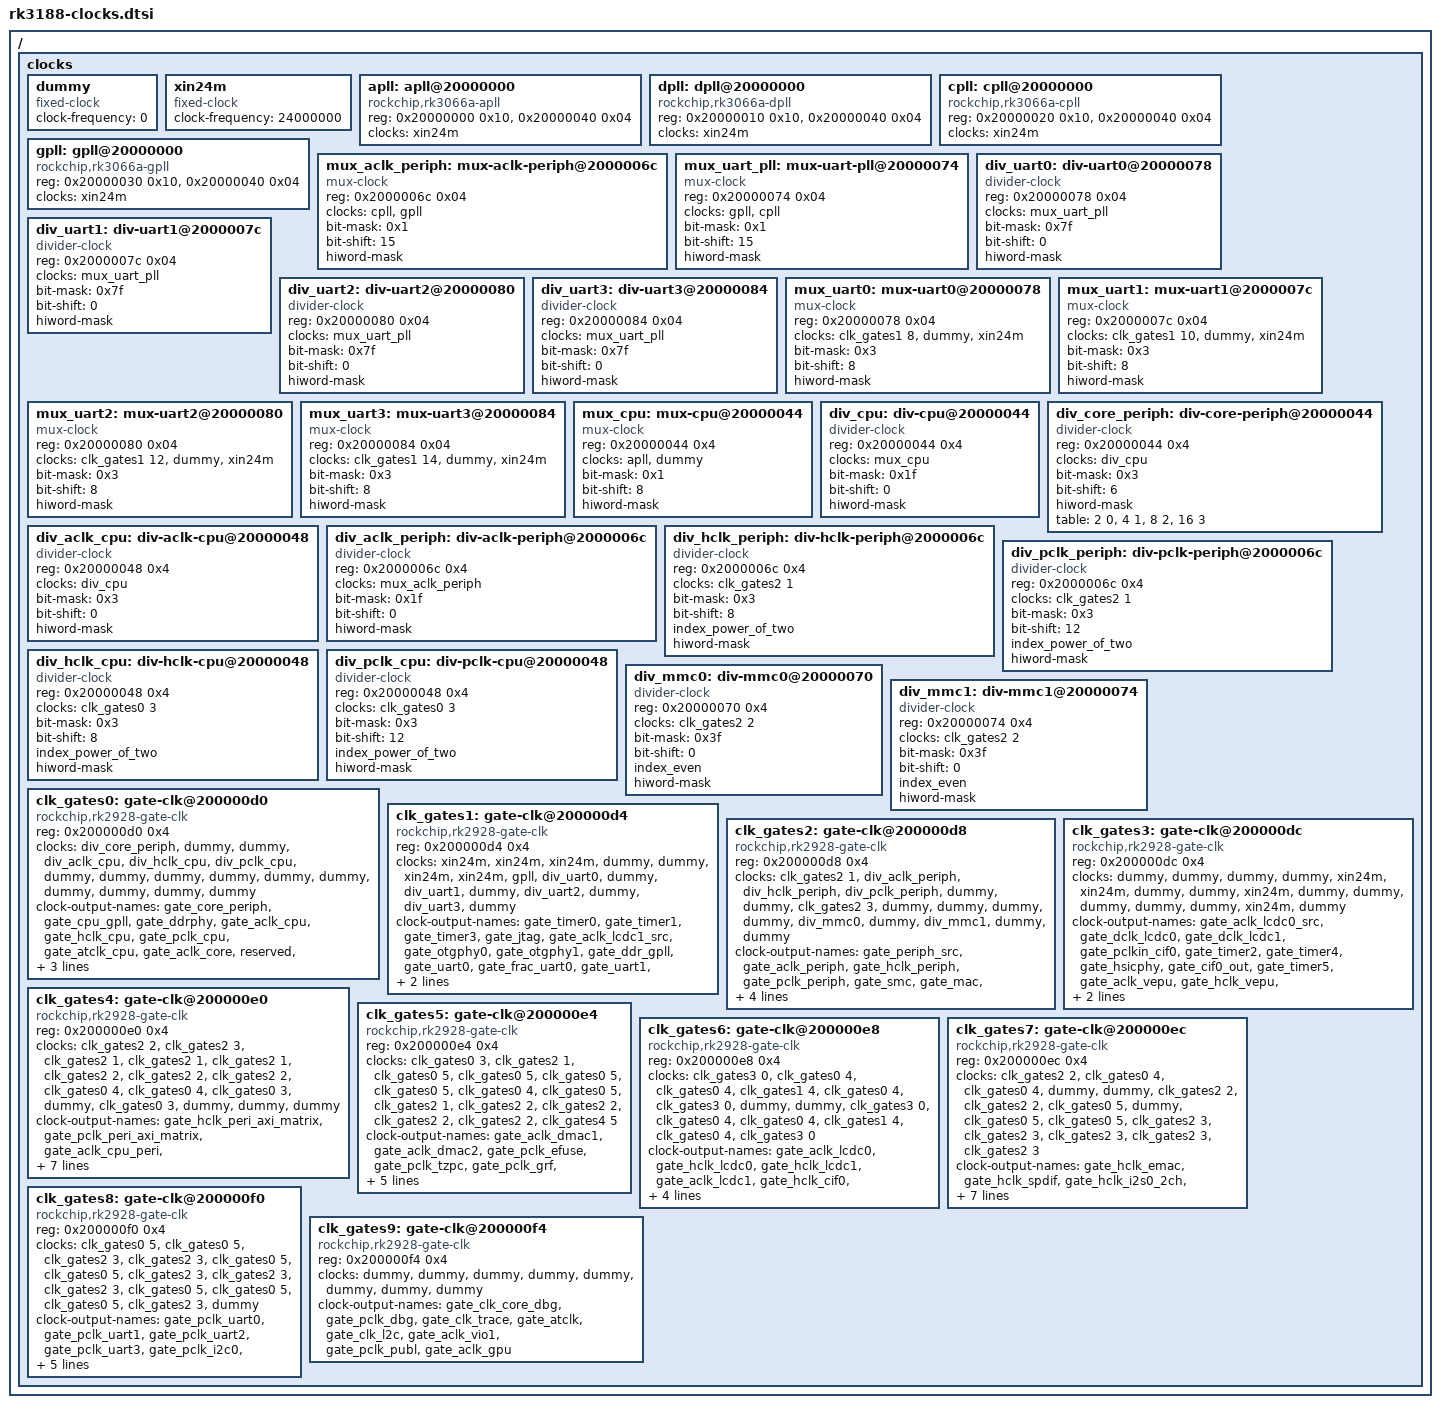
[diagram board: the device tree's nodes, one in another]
/*
 * Copyright (c) 2013 Ulrich Prinz <ulrich.prinz@googlemail.com>
 * based on rk3066-clocks.dtsi
 * Copyright (c) 2013 MundoReader S.L.
 * Author: Heiko Stuebner <heiko@sntech.de>
 *
 * This program is free software; you can redistribute it and/or modify
 * it under the terms of the GNU General Public License as published by
 * the Free Software Foundation; either version 2 of the License, or
 * (at your option) any later version.
 *
 * This program is distributed in the hope that it will be useful,
 * but WITHOUT ANY WARRANTY; without even the implied warranty of
 * MERCHANTABILITY or FITNESS FOR A PARTICULAR PURPOSE.  See the
 * GNU General Public License for more details.
 */

/ {
	clocks {
		#address-cells = <1>;
		#size-cells = <1>;
		ranges;

		/*
		 * This is a dummy clock, to be used as placeholder on
		 * other mux clocks when a specific parent clock is not
		 * yet implemented. It should be dropped when the driver
		 * is complete.
		 */
		dummy: dummy {
			compatible = "fixed-clock";
			clock-frequency = <0>;
			#clock-cells = <0>;
		};

		xin24m: xin24m {
			compatible = "fixed-clock";
			clock-frequency = <24000000>;
			#clock-cells = <0>;
		};

		apll: apll@20000000 {
			compatible = "rockchip,rk3066a-apll";
			reg = <0x20000000 0x10>,
			      <0x20000040 0x04>;
			clocks = <&xin24m>;
 			#clock-cells = <0>;
 		};

		dpll: dpll@20000000 {
			compatible = "rockchip,rk3066a-dpll";
			reg = <0x20000010 0x10>,
			      <0x20000040 0x04>;
			clocks = <&xin24m>;
			#clock-cells = <0>;
		};

		cpll: cpll@20000000 {
			compatible = "rockchip,rk3066a-cpll";
			reg = <0x20000020 0x10>,
			      <0x20000040 0x04>;
			clocks = <&xin24m>;
			#clock-cells = <0>;
		};

		gpll: gpll@20000000 {
			compatible = "rockchip,rk3066a-gpll";
			reg = <0x20000030 0x10>,
			      <0x20000040 0x04>;
			clocks = <&xin24m>;
			#clock-cells = <0>;
		};

		/* TODO: mux_ddr: missing */

		mux_aclk_periph: mux-aclk-periph@2000006c {
			compatible = "mux-clock";
			reg = <0x2000006c 0x04>;
			clocks = <&cpll>, <&gpll>;
			bit-mask = <0x1>;
			bit-shift = <15>;
			hiword-mask;
			#clock-cells = <0>;
		};

		mux_uart_pll: mux-uart-pll@20000074 {
			compatible = "mux-clock";
			reg = <0x20000074 0x04>;
			clocks = <&gpll>, <&cpll>;
			bit-mask = <0x1>;
			bit-shift = <15>;
			hiword-mask;
			#clock-cells = <0>;
		};

		div_uart0: div-uart0@20000078 {
			compatible = "divider-clock";
			reg = <0x20000078 0x04>;
			clocks = <&mux_uart_pll>;
			bit-mask = <0x7f>;
			bit-shift = <0>;
			hiword-mask;
			#clock-cells = <0>;
		};

		div_uart1: div-uart1@2000007c {
			compatible = "divider-clock";
			reg = <0x2000007c 0x04>;
			clocks = <&mux_uart_pll>;
			bit-mask = <0x7f>;
			bit-shift = <0>;
			hiword-mask;
			#clock-cells = <0>;
		};

		div_uart2: div-uart2@20000080 {
			compatible = "divider-clock";
			reg = <0x20000080 0x04>;
			clocks = <&mux_uart_pll>;
			bit-mask = <0x7f>;
			bit-shift = <0>;
			hiword-mask;
			#clock-cells = <0>;
		};

		div_uart3: div-uart3@20000084 {
			compatible = "divider-clock";
			reg = <0x20000084 0x04>;
			clocks = <&mux_uart_pll>;
			bit-mask = <0x7f>;
			bit-shift = <0>;
			hiword-mask;
			#clock-cells = <0>;
		};

		mux_uart0: mux-uart0@20000078 {
			compatible = "mux-clock";
			reg = <0x20000078 0x04>;
			clocks = <&clk_gates1 8>, <&dummy>, <&xin24m>; /* dummy is uart0_frac_div */
			bit-mask = <0x3>;
			bit-shift = <8>;
			hiword-mask;
			#clock-cells = <0>;
		};

		mux_uart1: mux-uart1@2000007c {
			compatible = "mux-clock";
			reg = <0x2000007c 0x04>;
			clocks = <&clk_gates1 10>, <&dummy>, <&xin24m>;
			bit-mask = <0x3>;
			bit-shift = <8>;
			hiword-mask;
			#clock-cells = <0>;
		};

		mux_uart2: mux-uart2@20000080 {
			compatible = "mux-clock";
			reg = <0x20000080 0x04>;
			clocks = <&clk_gates1 12>, <&dummy>, <&xin24m>;
			bit-mask = <0x3>;
			bit-shift = <8>;
			hiword-mask;
			#clock-cells = <0>;
		};

		mux_uart3: mux-uart3@20000084 {
			compatible = "mux-clock";
			reg = <0x20000084 0x04>;
			clocks = <&clk_gates1 14>, <&dummy>, <&xin24m>;
			bit-mask = <0x3>;
			bit-shift = <8>;
			hiword-mask;
			#clock-cells = <0>;
		};

		mux_cpu: mux-cpu@20000044 {
			compatible = "mux-clock";
			reg = <0x20000044 0x4>;
			clocks = <&apll>, <&dummy> /* cpu_gpll_path */;
			bit-mask = <0x1>;
			bit-shift = <8>;
			hiword-mask;
			#clock-cells = <0>;
		};

		div_cpu: div-cpu@20000044 {
			compatible = "divider-clock";
			reg = <0x20000044 0x4>;
			clocks = <&mux_cpu>;
			bit-mask = <0x1f>;
			bit-shift = <0>;
			hiword-mask;
			#clock-cells = <0>;
		};

		div_core_periph: div-core-periph@20000044 {
			compatible = "divider-clock";
			reg = <0x20000044 0x4>;
			clocks = <&div_cpu>;
			bit-mask = <0x3>;
			bit-shift = <6>;
			hiword-mask;
			table = <2 0>, <4 1>, <8 2>, <16 3>;
			#clock-cells = <0>;
		};

		div_aclk_cpu: div-aclk-cpu@20000048 {
			compatible = "divider-clock";
			reg = <0x20000048 0x4>;
			clocks = <&div_cpu>;
			bit-mask = <0x3>;
			bit-shift = <0>;
			hiword-mask;
			#clock-cells = <0>;
		};

		div_aclk_periph: div-aclk-periph@2000006c {
			compatible = "divider-clock";
			reg = <0x2000006c 0x4>;
			clocks = <&mux_aclk_periph>;
			bit-mask = <0x1f>;
			bit-shift = <0>;
			hiword-mask;
			#clock-cells = <0>;
		};

		div_hclk_periph: div-hclk-periph@2000006c {
			compatible = "divider-clock";
			reg = <0x2000006c 0x4>;
			clocks = <&clk_gates2 1>;
			bit-mask = <0x3>;
			bit-shift = <8>;
			index_power_of_two;
			hiword-mask;
			#clock-cells = <0>;
		};

		div_pclk_periph: div-pclk-periph@2000006c {
			compatible = "divider-clock";
			reg = <0x2000006c 0x4>;
			clocks = <&clk_gates2 1>;
			bit-mask = <0x3>;
			bit-shift = <12>;
			index_power_of_two;
			hiword-mask;
			#clock-cells = <0>;
		};

		div_hclk_cpu: div-hclk-cpu@20000048 {
			compatible = "divider-clock";
			reg = <0x20000048 0x4>;
			clocks = <&clk_gates0 3>;
			bit-mask = <0x3>;
			bit-shift = <8>;
			index_power_of_two;
			hiword-mask;
			#clock-cells = <0>;
		};

		div_pclk_cpu: div-pclk-cpu@20000048 {
			compatible = "divider-clock";
			reg = <0x20000048 0x4>;
			clocks = <&clk_gates0 3>;
			bit-mask = <0x3>;
			bit-shift = <12>;
			index_power_of_two;
			hiword-mask;
			#clock-cells = <0>;
		};

		div_mmc0: div-mmc0@20000070 {
			compatible = "divider-clock";
			reg = <0x20000070 0x4>;
			clocks = <&clk_gates2 2>;
			bit-mask = <0x3f>;
			bit-shift = <0>;
			index_even;
			hiword-mask;
			#clock-cells = <0>;
		};

		div_mmc1: div-mmc1@20000074 {
			compatible = "divider-clock";
			reg = <0x20000074 0x4>;
			clocks = <&clk_gates2 2>;
			bit-mask = <0x3f>;
			bit-shift = <0>;
			index_even;
			hiword-mask;
 			#clock-cells = <0>;
 		};
 		
		clk_gates0: gate-clk@200000d0 {
			compatible = "rockchip,rk2928-gate-clk";
			reg = <0x200000d0 0x4>;
			clocks = 
				 <&div_core_periph>, <&dummy>,
				 <&dummy>, <&div_aclk_cpu>,
				 <&div_hclk_cpu>, <&div_pclk_cpu>,
				 <&dummy>, <&dummy>,
				 <&dummy>, <&dummy>,
				 <&dummy>, <&dummy>,
				 <&dummy>, <&dummy>,
				 <&dummy>, <&dummy>;

			clock-output-names =
				"gate_core_periph", "gate_cpu_gpll",
				"gate_ddrphy", "gate_aclk_cpu",
				"gate_hclk_cpu", "gate_pclk_cpu",
				"gate_atclk_cpu", "gate_aclk_core",
				"reserved", "gate_i2s0",
				"gate_i2s0_frac", "reserved",
				"reserved", "gate_spdif",
				"gate_spdif_frac", "gate_testclk";

			#clock-cells = <1>;
		};

		clk_gates1: gate-clk@200000d4 {
			compatible = "rockchip,rk2928-gate-clk";
			reg = <0x200000d4 0x4>;
			clocks = 
				 <&xin24m>, <&xin24m>,
				 <&xin24m>, <&dummy>,
				 <&dummy>, <&xin24m>,
				 <&xin24m>, <&gpll>,
				 <&div_uart0>, <&dummy>,
				 <&div_uart1>, <&dummy>,
				 <&div_uart2>, <&dummy>,
				 <&div_uart3>, <&dummy>;

			clock-output-names =
				"gate_timer0", "gate_timer1",
				"gate_timer3", "gate_jtag",
				"gate_aclk_lcdc1_src", "gate_otgphy0",
				"gate_otgphy1", "gate_ddr_gpll",
				"gate_uart0", "gate_frac_uart0",
				"gate_uart1", "gate_frac_uart1",
				"gate_uart2", "gate_frac_uart2",
				"gate_uart3", "gate_frac_uart3";

			#clock-cells = <1>;
		};

		clk_gates2: gate-clk@200000d8 {
			compatible = "rockchip,rk2928-gate-clk";
			reg = <0x200000d8 0x4>;
			clocks = <&clk_gates2 1>, <&div_aclk_periph>,
				 <&div_hclk_periph>, <&div_pclk_periph>,
				 <&dummy>, <&dummy>,
				 <&clk_gates2 3>, <&dummy>,
				 <&dummy>, <&dummy>,
				 <&dummy>, <&div_mmc0>,
				 <&dummy>, <&div_mmc1>,
				 <&dummy>, <&dummy>;

			clock-output-names =
				"gate_periph_src", "gate_aclk_periph",
				"gate_hclk_periph", "gate_pclk_periph",
				"gate_smc", "gate_mac",
				"gate_hsadc", "gate_hsadc_frac",
				"gate_saradc", "gate_spi0",
				"gate_spi1", "gate_mmc0",
				"gate_mac_lbtest", "gate_mmc1",
				"gate_emmc", "reserved";

			#clock-cells = <1>;
		};

		clk_gates3: gate-clk@200000dc {
			compatible = "rockchip,rk2928-gate-clk";
			reg = <0x200000dc 0x4>;
			clocks = <&dummy>, <&dummy>,
				 <&dummy>, <&dummy>,
				 <&xin24m>, <&xin24m>,
				 <&dummy>, <&dummy>,
				 <&xin24m>, <&dummy>,
				 <&dummy>, <&dummy>,
				 <&dummy>, <&dummy>,
				 <&xin24m>, <&dummy>;

			clock-output-names =
				"gate_aclk_lcdc0_src", "gate_dclk_lcdc0",
				"gate_dclk_lcdc1", "gate_pclkin_cif0",
				"gate_timer2", "gate_timer4",
				"gate_hsicphy", "gate_cif0_out",
				"gate_timer5", "gate_aclk_vepu",
				"gate_hclk_vepu", "gate_aclk_vdpu",
				"gate_hclk_vdpu", "reserved",
				"gate_timer6", "gate_aclk_gpu_src";

			#clock-cells = <1>;
		};

		clk_gates4: gate-clk@200000e0 {
			compatible = "rockchip,rk2928-gate-clk";
			reg = <0x200000e0 0x4>;
			clocks = <&clk_gates2 2>, <&clk_gates2 3>,
				 <&clk_gates2 1>, <&clk_gates2 1>,
				 <&clk_gates2 1>, <&clk_gates2 2>,
				 <&clk_gates2 2>, <&clk_gates2 2>,
				 <&clk_gates0 4>, <&clk_gates0 4>,
				 <&clk_gates0 3>, <&dummy>,
				 <&clk_gates0 3>, <&dummy>,
				 <&dummy>, <&dummy>;

			clock-output-names =
				"gate_hclk_peri_axi_matrix", "gate_pclk_peri_axi_matrix",
				"gate_aclk_cpu_peri", "gate_aclk_peri_axi_matrix",
				"gate_aclk_pei_niu", "gate_hclk_usb_peri",
				"gate_hclk_peri_ahb_arbi", "gate_hclk_emem_peri",
				"gate_hclk_cpubus", "gate_hclk_ahb2apb",
				"gate_aclk_strc_sys", "reserved",
				"gate_aclk_intmem", "reserved",
				"gate_hclk_imem1", "gate_hclk_imem0";

			#clock-cells = <1>;
		};

		clk_gates5: gate-clk@200000e4 {
			compatible = "rockchip,rk2928-gate-clk";
			reg = <0x200000e4 0x4>;
			clocks = 
				 <&clk_gates0 3>, <&clk_gates2 1>,
				 <&clk_gates0 5>, <&clk_gates0 5>,
				 <&clk_gates0 5>, <&clk_gates0 5>,
				 <&clk_gates0 4>, <&clk_gates0 5>,
				 <&clk_gates2 1>, <&clk_gates2 2>,
				 <&clk_gates2 2>, <&clk_gates2 2>,
				 <&clk_gates2 2>, <&clk_gates4 5>;
				
			clock-output-names =
				"gate_aclk_dmac1", "gate_aclk_dmac2",
				"gate_pclk_efuse", "gate_pclk_tzpc",
				"gate_pclk_grf", "gate_pclk_pmu",
				"gate_hclk_rom", "gate_pclk_ddrupctl",
				"gate_aclk_smc", "gate_hclk_nandc",
				"gate_hclk_mmc0", "gate_hclk_mmc1",
				"gate_hclk_emmc", "gate_hclk_otg0";

			#clock-cells = <1>;
		};

		clk_gates6: gate-clk@200000e8 {
			compatible = "rockchip,rk2928-gate-clk";
			reg = <0x200000e8 0x4>;
			clocks = 
				 <&clk_gates3 0>, <&clk_gates0 4>,
				 <&clk_gates0 4>, <&clk_gates1 4>,
				 <&clk_gates0 4>, <&clk_gates3 0>,
				 <&dummy>, <&dummy>,
				 <&clk_gates3 0>, <&clk_gates0 4>,
				 <&clk_gates0 4>, <&clk_gates1 4>,
				 <&clk_gates0 4>, <&clk_gates3 0>;

			clock-output-names =
				"gate_aclk_lcdc0", "gate_hclk_lcdc0",
				"gate_hclk_lcdc1", "gate_aclk_lcdc1",
				"gate_hclk_cif0", "gate_aclk_cif0",
				"reserved", "reserved",
				"gate_aclk_ipp", "gate_hclk_ipp",
				"gate_hclk_rga", "gate_aclk_rga",
				"gate_hclk_vio_bus", "gate_aclk_vio0";

			#clock-cells = <1>;
		};

		clk_gates7: gate-clk@200000ec {
			compatible = "rockchip,rk2928-gate-clk";
			reg = <0x200000ec 0x4>;
			clocks = 
				 <&clk_gates2 2>, <&clk_gates0 4>,
				 <&clk_gates0 4>, <&dummy>, /*<&clk_gbla>,*/
				 <&dummy>, /*<&clk_bla>,*/ <&clk_gates2 2>,
				 <&clk_gates2 2>, <&clk_gates0 5>,
				 <&dummy>, <&clk_gates0 5>,
				 <&clk_gates0 5>, <&clk_gates2 3>,
				 <&clk_gates2 3>, <&clk_gates2 3>,
				 <&clk_gates2 3>, <&clk_gates2 3>;

			clock-output-names =
				"gate_hclk_emac", "gate_hclk_spdif",
				"gate_hclk_i2s0_2ch", "gate_hclk_otg1",
				"gate_hclk_hsic", "gate_hclk_hsadc",
				"gate_hclk_pidf", "gate_pclk_timer0",
				"reserved", "gate_pclk_timer2",
				"gate_pclk_pwm01", "gate_pclk_pwm23",
				"gate_pclk_spi0", "gate_pclk_spi1",
				"gate_pclk_saradc", "gate_pclk_wdt";

			#clock-cells = <1>;
		};

		clk_gates8: gate-clk@200000f0 {
			compatible = "rockchip,rk2928-gate-clk";
			reg = <0x200000f0 0x4>;
			clocks = 
				 <&clk_gates0 5>, <&clk_gates0 5>,
				 <&clk_gates2 3>, <&clk_gates2 3>,
				 <&clk_gates0 5>, <&clk_gates0 5>,
				 <&clk_gates2 3>, <&clk_gates2 3>,
				 <&clk_gates2 3>, <&clk_gates0 5>,
				 <&clk_gates0 5>, <&clk_gates0 5>,
				 <&clk_gates2 3>, <&dummy> /*<&clk_gatbla>*/;

			clock-output-names =
				"gate_pclk_uart0", "gate_pclk_uart1",
				"gate_pclk_uart2", "gate_pclk_uart3",
				"gate_pclk_i2c0", "gate_pclk_i2c1",
				"gate_pclk_i2c2", "gate_pclk_i2c3",
				"gate_pclk_i2c4", "gate_pclk_gpio0",
				"gate_pclk_gpio1", "gate_pclk_gpio2",
				"gate_pclk_gpio3", "gate_aclk_gps";

			#clock-cells = <1>;
		};

		clk_gates9: gate-clk@200000f4 {
			compatible = "rockchip,rk2928-gate-clk";
			reg = <0x200000f4 0x4>;
			clocks = 
				 <&dummy>, <&dummy>, /*<&clk_gates0 5xx>,*/
				 <&dummy>, <&dummy>,
				 <&dummy>, <&dummy>, /*<&clk_gates1 4xx>,*/
				 <&dummy>, /*<&clk_gates0 5xx>,*/ <&dummy>;

			clock-output-names =
				"gate_clk_core_dbg", "gate_pclk_dbg",
				"gate_clk_trace", "gate_atclk",
				"gate_clk_l2c", "gate_aclk_vio1",
				"gate_pclk_publ", "gate_aclk_gpu";

			#clock-cells = <1>;
		};
	};

};
